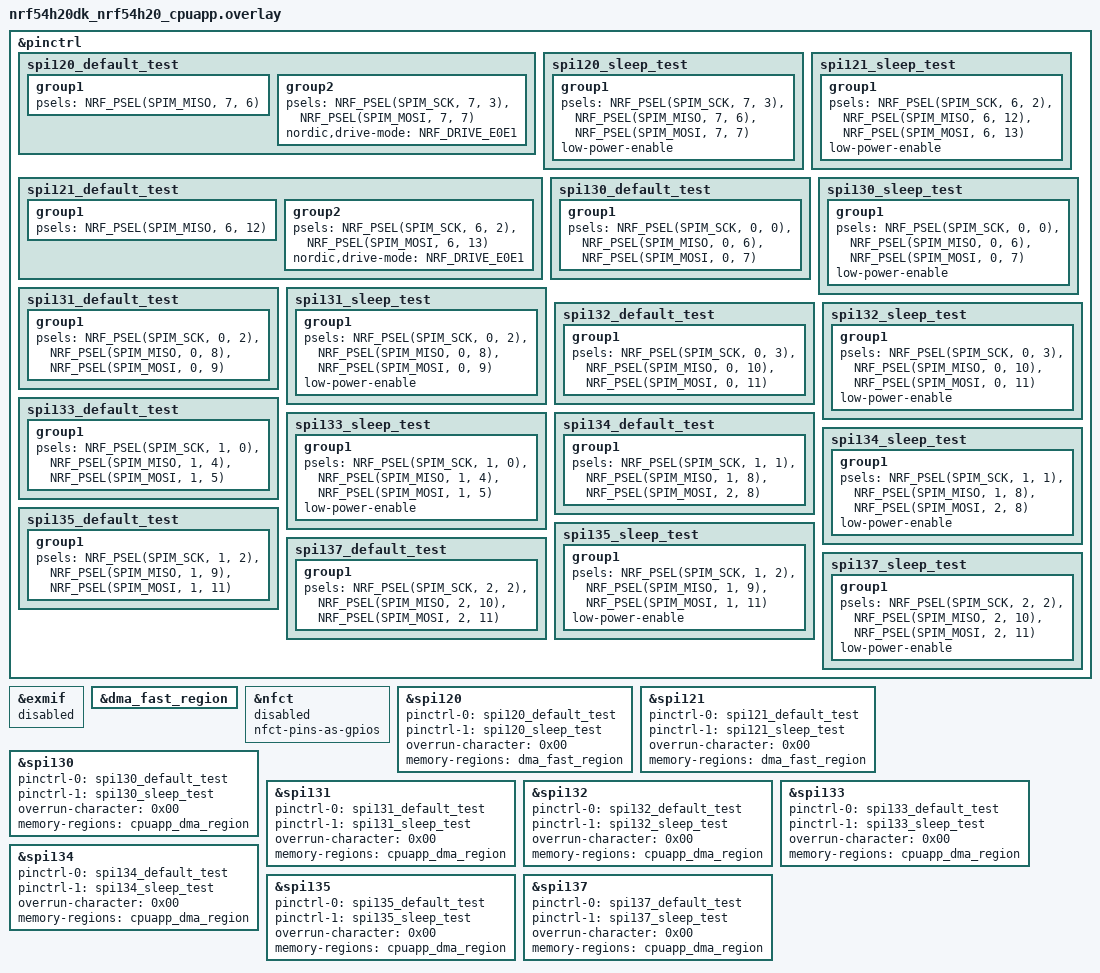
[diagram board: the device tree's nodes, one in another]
/*
 * Copyright (c) 2025 Nordic Semiconductor ASA
 *
 * SPDX-License-Identifier: LicenseRef-Nordic-5-Clause
 */

&pinctrl {
	spi120_default_test: spi120_default_test {
		group1 {
			psels = <NRF_PSEL(SPIM_MISO, 7, 6)>;
		};

		group2 {
			psels = <NRF_PSEL(SPIM_SCK, 7, 3)>,
				<NRF_PSEL(SPIM_MOSI, 7, 7)>;
			nordic,drive-mode = <NRF_DRIVE_E0E1>;
		};
	};

	spi120_sleep_test: spi120_sleep_test {
		group1 {
			psels = <NRF_PSEL(SPIM_SCK, 7, 3)>,
				<NRF_PSEL(SPIM_MISO, 7, 6)>,
				<NRF_PSEL(SPIM_MOSI, 7, 7)>;
			low-power-enable;
		};
	};

	spi121_default_test: spi121_default_test {
		group1 {
			psels = <NRF_PSEL(SPIM_MISO, 6, 12)>;
		};

		group2 {
			psels = <NRF_PSEL(SPIM_SCK, 6, 2)>,
				<NRF_PSEL(SPIM_MOSI, 6, 13)>;
			nordic,drive-mode = <NRF_DRIVE_E0E1>;
		};
	};

	spi121_sleep_test: spi121_sleep_test {
		group1 {
			psels = <NRF_PSEL(SPIM_SCK, 6, 2)>,
				<NRF_PSEL(SPIM_MISO, 6, 12)>,
				<NRF_PSEL(SPIM_MOSI, 6, 13)>;
			low-power-enable;
		};
	};

	spi130_default_test: spi130_default_test {
		group1 {
			psels = <NRF_PSEL(SPIM_SCK, 0, 0)>,
				<NRF_PSEL(SPIM_MISO, 0, 6)>,
				<NRF_PSEL(SPIM_MOSI, 0, 7)>;
		};
	};

	spi130_sleep_test: spi130_sleep_test {
		group1 {
			psels = <NRF_PSEL(SPIM_SCK, 0, 0)>,
				<NRF_PSEL(SPIM_MISO, 0, 6)>,
				<NRF_PSEL(SPIM_MOSI, 0, 7)>;
			low-power-enable;
		};
	};

	spi131_default_test: spi131_default_test {
		group1 {
			psels = <NRF_PSEL(SPIM_SCK, 0, 2)>,
				<NRF_PSEL(SPIM_MISO, 0, 8)>,
				<NRF_PSEL(SPIM_MOSI, 0, 9)>;
		};
	};

	spi131_sleep_test: spi131_sleep_test {
		group1 {
			psels = <NRF_PSEL(SPIM_SCK, 0, 2)>,
				<NRF_PSEL(SPIM_MISO, 0, 8)>,
				<NRF_PSEL(SPIM_MOSI, 0, 9)>;
			low-power-enable;
		};
	};

	spi132_default_test: spi132_default_test {
		group1 {
			psels = <NRF_PSEL(SPIM_SCK, 0, 3)>,
				<NRF_PSEL(SPIM_MISO, 0, 10)>,
				<NRF_PSEL(SPIM_MOSI, 0, 11)>;
		};
	};

	spi132_sleep_test: spi132_sleep_test {
		group1 {
			psels = <NRF_PSEL(SPIM_SCK, 0, 3)>,
				<NRF_PSEL(SPIM_MISO, 0, 10)>,
				<NRF_PSEL(SPIM_MOSI, 0, 11)>;
			low-power-enable;
		};
	};

	spi133_default_test: spi133_default_test {
		group1 {
			psels = <NRF_PSEL(SPIM_SCK, 1, 0)>,
				<NRF_PSEL(SPIM_MISO, 1, 4)>,
				<NRF_PSEL(SPIM_MOSI, 1, 5)>;
		};
	};

	spi133_sleep_test: spi133_sleep_test {
		group1 {
			psels = <NRF_PSEL(SPIM_SCK, 1, 0)>,
				<NRF_PSEL(SPIM_MISO, 1, 4)>,
				<NRF_PSEL(SPIM_MOSI, 1, 5)>;
			low-power-enable;
		};
	};

	spi134_default_test: spi134_default_test {
		group1 {
			psels = <NRF_PSEL(SPIM_SCK, 1, 1)>,
				<NRF_PSEL(SPIM_MISO, 1, 8)>,
				<NRF_PSEL(SPIM_MOSI, 2, 8)>;
		};
	};

	spi134_sleep_test: spi134_sleep_test {
		group1 {
			psels = <NRF_PSEL(SPIM_SCK, 1, 1)>,
				<NRF_PSEL(SPIM_MISO, 1, 8)>,
				<NRF_PSEL(SPIM_MOSI, 2, 8)>;
			low-power-enable;
		};
	};

	spi135_default_test: spi135_default_test {
		group1 {
			psels = <NRF_PSEL(SPIM_SCK, 1, 2)>,
				<NRF_PSEL(SPIM_MISO, 1, 9)>,
				<NRF_PSEL(SPIM_MOSI, 1, 11)>;
		};
	};

	spi135_sleep_test: spi135_sleep_test {
		group1 {
			psels = <NRF_PSEL(SPIM_SCK, 1, 2)>,
				<NRF_PSEL(SPIM_MISO, 1, 9)>,
				<NRF_PSEL(SPIM_MOSI, 1, 11)>;
			low-power-enable;
		};
	};

	spi137_default_test: spi137_default_test {
		group1 {
			psels = <NRF_PSEL(SPIM_SCK, 2, 2)>,
				<NRF_PSEL(SPIM_MISO, 2, 10)>,
				<NRF_PSEL(SPIM_MOSI, 2, 11)>;
		};
	};

	spi137_sleep_test: spi137_sleep_test {
		group1 {
			psels = <NRF_PSEL(SPIM_SCK, 2, 2)>,
				<NRF_PSEL(SPIM_MISO, 2, 10)>,
				<NRF_PSEL(SPIM_MOSI, 2, 11)>;
			low-power-enable;
		};
	};
};

&exmif {
	status = "disabled";
};

&dma_fast_region {
	status = "okay";
};

&nfct {
	status = "disabled";
	nfct-pins-as-gpios;
};

&spi120 {
	status = "okay";
	pinctrl-0 = <&spi120_default_test>;
	pinctrl-1 = <&spi120_sleep_test>;
	pinctrl-names = "default", "sleep";
	overrun-character = <0x00>;
	memory-regions = <&dma_fast_region>;
};

&spi121 {
	status = "okay";
	pinctrl-0 = <&spi121_default_test>;
	pinctrl-1 = <&spi121_sleep_test>;
	pinctrl-names = "default", "sleep";
	overrun-character = <0x00>;
	memory-regions = <&dma_fast_region>;
};

&spi130 {
	status = "okay";
	pinctrl-0 = <&spi130_default_test>;
	pinctrl-1 = <&spi130_sleep_test>;
	pinctrl-names = "default", "sleep";
	overrun-character = <0x00>;
	memory-regions = <&cpuapp_dma_region>;
};

&spi131 {
	status = "okay";
	pinctrl-0 = <&spi131_default_test>;
	pinctrl-1 = <&spi131_sleep_test>;
	pinctrl-names = "default", "sleep";
	overrun-character = <0x00>;
	memory-regions = <&cpuapp_dma_region>;
};

&spi132 {
	status = "okay";
	pinctrl-0 = <&spi132_default_test>;
	pinctrl-1 = <&spi132_sleep_test>;
	pinctrl-names = "default", "sleep";
	overrun-character = <0x00>;
	memory-regions = <&cpuapp_dma_region>;
};

&spi133 {
	status = "okay";
	pinctrl-0 = <&spi133_default_test>;
	pinctrl-1 = <&spi133_sleep_test>;
	pinctrl-names = "default", "sleep";
	overrun-character = <0x00>;
	memory-regions = <&cpuapp_dma_region>;
};

&spi134 {
	status = "okay";
	pinctrl-0 = <&spi134_default_test>;
	pinctrl-1 = <&spi134_sleep_test>;
	pinctrl-names = "default", "sleep";
	overrun-character = <0x00>;
	memory-regions = <&cpuapp_dma_region>;
};

&spi135 {
	status = "okay";
	pinctrl-0 = <&spi135_default_test>;
	pinctrl-1 = <&spi135_sleep_test>;
	pinctrl-names = "default", "sleep";
	overrun-character = <0x00>;
	memory-regions = <&cpuapp_dma_region>;
};

/* spi136 inaccessible due to console on uart136 */

&spi137 {
	status = "okay";
	pinctrl-0 = <&spi137_default_test>;
	pinctrl-1 = <&spi137_sleep_test>;
	pinctrl-names = "default", "sleep";
	overrun-character = <0x00>;
	memory-regions = <&cpuapp_dma_region>;
};
